# STM32H7S register map
File version: 1.0
CPU: CM7 r0p1, little endian, MPU, FPU, 4 interrupt priority bits
Registers are 32-bit, read-write, reset 0x0 unless marked. A register's access mark holds for its fields unless they carry their own. Offsets are from the block's base; [hi:lo] are bit positions; <NAME> marks a mode.

## TIM13 — General-purpose timers
Base 0x40001C00
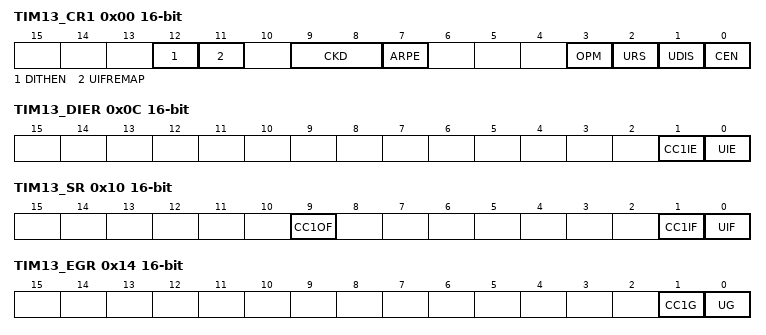
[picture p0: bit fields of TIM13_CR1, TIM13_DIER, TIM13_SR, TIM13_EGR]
0x00 TIM13_CR1 16-bit — TIM13 control register 1
  [12] DITHEN — Dithering enable Note: The DITHEN bit can only be modified when CEN bit is reset.
    0=Dithering disabled; 1=Dithering enabled
  [11] UIFREMAP — UIF status bit remapping
    0=No remapping. UIF status bit is not copied to TIMx_CNT register bit 31.; 1=Remapping enabled. UIF status bit is copied to TIMx_CNT register bit 31.
  [9:8] CKD — Clock division This bit-field indicates the division ratio between the timer clock (tim_ker_ck) frequency and sampling clock used by the digital filters (tim_tix),
    0=t<sub>DTS</sub> = t<sub>tim_ker_ck</sub>; 1=t<sub>DTS</sub> = 2 t<sub>tim_ker_ck</sub>; 2=t<sub>DTS</sub> = 4 t<sub>tim_ker_ck</sub>; 3=FIELD Reserved
  [7] ARPE — Auto-reload preload enable
    0=TIMx_ARR register is not buffered; 1=TIMx_ARR register is buffered
  [3] OPM — One-pulse mode
    0=Counter is not stopped on the update event; 1=Counter stops counting on the next update event (clearing the CEN bit)
  [2] URS — Update request source This bit is set and cleared by software to select the update interrupt (UEV) sources. Counter overflow Setting the UG bit
    0=Any of the following events generate an UEV if enabled:; 1=Only counter overflow generates an UEV if enabled
  [1] UDIS — Update disable This bit is set and cleared by software to enable/disable update interrupt (UEV) event generation. Counter overflow Setting the UG bit. Buffered registers are then loaded with their preload values.
    0=UEV enabled. An UEV is generated by one of the following events:; 1=UEV disabled. No UEV is generated, shadow registers keep their value (ARR, PSC, CCRx). The counter and the prescaler are reinitialized if the UG bit is set.
  [0] CEN — Counter enable Note: External clock and gated mode can work only if the CEN bit has been previously set by software. However trigger mode can set the CEN bit automatically by hardware.
    0=Counter disabled; 1=Counter enabled
0x0C TIM13_DIER 16-bit — TIM13 Interrupt enable register
  [1] CC1IE — Capture/Compare 1 interrupt enable
    0=CC1 interrupt disabled; 1=CC1 interrupt enabled
  [0] UIE — Update interrupt enable
    0=Update interrupt disabled; 1=Update interrupt enabled
0x10 TIM13_SR 16-bit — TIM13 status register
  [9] CC1OF — Capture/Compare 1 overcapture flag This flag is set by hardware only when the corresponding channel is configured in input capture mode. It is cleared by software by writing it to 0.
    0=No overcapture has been detected; 1=The counter value has been captured in TIMx_CCR1 register while CC1IF flag was already set
  [1] CC1IF — Capture/compare 1 interrupt flag This flag is set by hardware. It is cleared by software (input capture or output compare mode) or by reading the TIMx_CCR1 register (input capture mode only). If channel CC1 is configured as output: this flag is set when he content of the counter TIMx_CNT matches the content of the TIMx_CCR1 register. When the content of TIMx_CCR1 is greater than the content of TIMx_ARR, the CC1IF bit goes high on the counter overflow (in up-counting and up/down-counting modes) or underflow (in down-counting mode). There are 3 possible options for flag setting in center-aligned mode, refer to the CMS bits in the TIMx_CR1 register for the full description. If channel CC1 is configured as input: this bit is set when counter value has been captured in TIMx_CCR1 register (an edge has been detected on tim_ic1, as per the edge sensitivity defined with the CC1P and CC1NP bits setting, in TIMx_CCER).
    0=No compare match / No input capture occurred; 1=A compare match or an input capture occurred
  [0] UIF — Update interrupt flag This bit is set by hardware on an update event. It is cleared by software. At overflow and if UDIS=0 in the TIMx_CR1 register. When CNT is reinitialized by software using the UG bit in TIMx_EGR register, if URS=0 and UDIS=0 in the TIMx_CR1 register.
    0=No update occurred; 1=Update interrupt pending. This bit is set by hardware when the registers are updated:
0x14 TIM13_EGR 16-bit wo — TIM13 event generation register
  [1] CC1G — Capture/compare 1 generation This bit is set by software in order to generate an event, it is automatically cleared by hardware. If channel CC1 is configured as output: CC1IF flag is set, Corresponding interrupt or is sent if enabled. If channel CC1 is configured as input: The current value of the counter is captured in TIMx_CCR1 register. The CC1IF flag is set, the corresponding interrupt is sent if enabled. The CC1OF flag is set if the CC1IF flag was already high.
    0=No action; 1=A capture/compare event is generated on channel 1:
  [0] UG — Update generation This bit can be set by software, it is automatically cleared by hardware.
    0=No action; 1=Re-initialize the counter and generates an update of the registers. Note that the prescaler counter is cleared too (anyway the prescaler ratio is not affected). The counter is cleared.
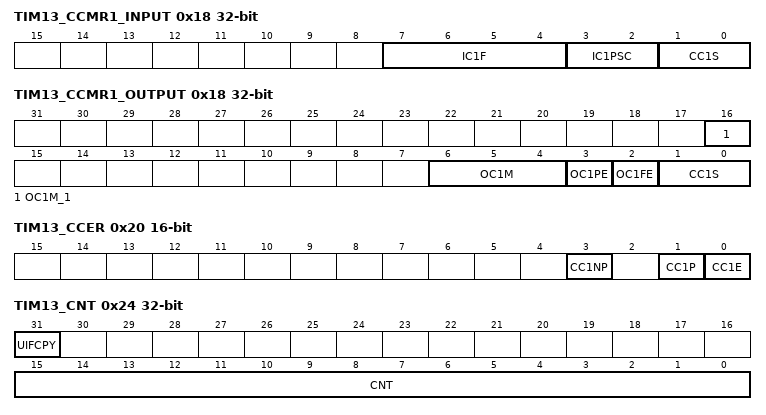
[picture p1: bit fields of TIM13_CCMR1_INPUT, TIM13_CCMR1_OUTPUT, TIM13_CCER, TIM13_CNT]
0x18 TIM13_CCMR1_INPUT — TIM13 capture/compare mode register 1
  [7:4] IC1F — Input capture 1 filter This bit-field defines the frequency used to sample tim_ti1 input and the length of the digital filter applied to tim_ti1. The digital filter is made of an event counter in which N consecutive events are needed to validate a transition on the output:
    0=No filter, sampling is done at f<sub>DTS</sub>; 1=f<sub>SAMPLING</sub>=f<sub>tim_ker_ck</sub>, N=2; 2=f<sub>SAMPLING</sub>=f<sub>tim_ker_ck</sub>, N=4; 3=f<sub>SAMPLING</sub>=f<sub>tim_ker_ck</sub>, N=8; 4=f<sub>SAMPLING</sub>=f<sub>DTS</sub>/2, N=6; 5=f<sub>SAMPLING</sub>=f<sub>DTS</sub>/2, N=8; 6=f<sub>SAMPLING</sub>=f<sub>DTS</sub>/4, N=6; 7=f<sub>SAMPLING</sub>=f<sub>DTS</sub>/4, N=8; 8=f<sub>SAMPLING</sub>=f<sub>DTS</sub>/8, N=6; 9=f<sub>SAMPLING</sub>=f<sub>DTS</sub>/8, N=8; 10=f<sub>SAMPLING</sub>=f<sub>DTS</sub>/16, N=5; 11=f<sub>SAMPLING</sub>=f<sub>DTS</sub>/16, N=6; 12=f<sub>SAMPLING</sub>=f<sub>DTS</sub>/16, N=8; 13=f<sub>SAMPLING</sub>=f<sub>DTS</sub>/32, N=5; 14=f<sub>SAMPLING</sub>=f<sub>DTS</sub>/32, N=6; 15=f<sub>SAMPLING</sub>=f<sub>DTS</sub>/32, N=8
  [3:2] IC1PSC — Input capture 1 prescaler This bit-field defines the ratio of the prescaler acting on CC1 input (tim_ic1). The prescaler is reset as soon as CC1E=0 (TIMx_CCER register).
    0=no prescaler, capture is done each time an edge is detected on the capture input; 1=capture is done once every 2 events; 2=capture is done once every 4 events; 3=capture is done once every 8 events
  [1:0] CC1S — Capture/Compare 1 selection This bit-field defines the direction of the channel (input/output) as well as the used input. Note: CC1S bits are writable only when the channel is OFF (CC1E = 0 in TIMx_CCER).
    0=CC1 channel is configured as output; 1=CC1 channel is configured as input, tim_ic1 is mapped on tim_ti1; 2=FIELD Reserved; 3=FIELD Reserved
0x18 TIM13_CCMR1_OUTPUT (alternate view of TIM13_CCMR1_INPUT) — TIM13 capture/compare mode register 1
  [16] OC1M_1 — OC1M[3]
  [6:4] OC1M — OC1M[2:0]: Output compare 1 mode (refer to bit 16 for OC1M[3]) These bits define the behavior of the output reference signal tim_oc1ref from which tim_oc1 is derived. tim_oc1ref is active high whereas tim_oc1 active level depends on CC1P bit. Others: Reserved Note: In PWM mode 1 or 2, the OCREF level changes when the result of the comparison changes or when the output compare mode switches from frozen to PWM mode.
    0=Frozen. The comparison between the output compare register TIMx_CCR1 and the counter TIMx_CNT has no effect on the outputs.; 1=Set channel 1 to active level on match. tim_oc1ref signal is forced high when the counter TIMx_CNT matches the capture/compare register 1 (TIMx_CCR1).; 2=Set channel 1 to inactive level on match. tim_oc1ref signal is forced low when the counter TIMx_CNT matches the capture/compare register 1 (TIMx_CCR1).; 3=Toggle - tim_oc1ref toggles when TIMx_CNT = TIMx_CCR1; 4=Force inactive level - tim_oc1ref is forced low; 5=Force active level - tim_oc1ref is forced high; 6=PWM mode 1 - Channel 1 is active as long as TIMx_CNT < TIMx_CCR1 else inactive; 7=PWM mode 2 - Channel 1 is inactive as long as TIMx_CNT < TIMx_CCR1 else active
  [3] OC1PE — Output compare 1 preload enable
    0=Preload register on TIMx_CCR1 disabled. TIMx_CCR1 can be written at anytime, the new value is taken in account immediately.; 1=Preload register on TIMx_CCR1 enabled. Read/Write operations access the preload register. TIMx_CCR1 preload value is loaded in the active register at each update event.
  [2] OC1FE — Output compare 1 fast enable This bit decreases the latency between a trigger event and a transition on the timer output. It must be used in one-pulse mode (OPM bit set in TIMx_CR1 register), to have the output pulse starting as soon as possible after the starting trigger.
    0=CC1 behaves normally depending on counter and CCR1 values even when the trigger is ON. The minimum delay to activate CC1 output when an edge occurs on the trigger input is 5 clock cycles.; 1=An active edge on the trigger input acts like a compare match on CC1 output. OC is then set to the compare level independently of the result of the comparison. Delay to sample the trigger input and to activate CC1 output is reduced to 3 clock cycles. OC1FE acts only if the channel is configured in PWM1 or PWM2 mode.
  [1:0] CC1S — Capture/Compare 1 selection This bit-field defines the direction of the channel (input/output) as well as the used input. Note: CC1S bits are writable only when the channel is OFF (CC1E = 0 in TIMx_CCER).
    0=CC1 channel is configured as output; 1=CC1 channel is configured as input, tim_ic1 is mapped on tim_ti1
0x20 TIM13_CCER 16-bit — TIM13 capture/compare enable register
  [3] CC1NP — Capture/Compare 1 complementary output Polarity. CC1 channel configured as output: CC1NP must be kept cleared. CC1 channel configured as input: CC1NP bit is used in conjunction with CC1P to define tim_ti1fp1 polarity (refer to CC1P description).
  [1] CC1P — Capture/Compare 1 output Polarity. When CC1 channel is configured as input, both CC1NP/CC1P bits select the active polarity of tim_ti1fp1 for capture operations. CC1NP=0, CC1P=0: non-inverted/rising edge. The circuit is sensitive to tim_ti1fp1 rising edge (capture or trigger operations in reset, external clock or trigger mode), TIxFP1 is not inverted (trigger operation in gated mode or encoder mode). CC1NP=0, CC1P=1: inverted/falling edge. The circuit is sensitive to tim_ti1fp1 falling edge (capture or trigger operations in reset, external clock or trigger mode), tim_ti1fp1 is inverted (trigger operation in gated mode or encoder mode). CC1NP=1, CC1P=1: non-inverted/both edges/ The circuit is sensitive to both tim_ti1fp1 rising and falling edges (capture or trigger operations in reset, external clock or trigger mode), tim_ti1fp1 not inverted (trigger operation in gated mode). This configuration must not be used in encoder mode. CC1NP=1, CC1P=0: This configuration is reserved, it must not be used.
    0=tim_oc1 active high (output mode) / Edge sensitivity selection (input mode, see below); 1=tim_oc1 active low (output mode) / Edge sensitivity selection (input mode, see below)
  [0] CC1E — Capture/Compare 1 output enable.
    0=Capture mode disabled / tim_oc1 is not active; 1=Capture mode enabled / tim_oc1 signal is output on the corresponding output pin
0x24 TIM13_CNT — TIM13 counter
  [31] UIFCPY — UIF Copy This bit is a read-only copy of the UIF bit in the TIMx_ISR register.
  [15:0] CNT — Counter value Non-dithering mode (DITHEN = 0) The register holds the counter value. Dithering mode (DITHEN = 1) The register only holds the non-dithered part in CNT[15:0]. The fractional part is not available.
0x28 TIM13_PSC 16-bit — TIM13 prescaler
  [15:0] PSC — Prescaler value The counter clock frequency tim_cnt_ck is equal to f<sub>tim_psc_ck</sub> / (PSC[15:0] + 1). PSC contains the value to be loaded in the active prescaler register at each update event. (including when the counter is cleared through UG bit of TIMx_EGR register or through trigger controller when configured in reset mode).
0x2C TIM13_ARR reset 0xFFFF — TIM13 auto-reload register
  [19:0] ARR — Auto-reload value ARR is the value to be loaded in the actual auto-reload register. Refer to the Section 67.4.3: Time-base unit on page 3951 for more details about ARR update and behavior. The counter is blocked while the auto-reload value is null. Non-dithering mode (DITHEN = 0) The register holds the auto-reload value in ARR[15:0]. The ARR[19:16] bits are reset. Dithering mode (DITHEN = 1) The register holds the integer part in ARR[19:4]. The ARR[3:0] bitfield contains the dithered part.
0x34 TIM13_CCR1 — TIM13 capture/compare register 1
  [19:0] CCR1 — Capture/compare 1 value If channel CC1 is configured as output: CCR1 is the value to be loaded in the actual capture/compare 1 register (preload value). It is loaded permanently if the preload feature is not selected in the TIMx_CCMR1 register (bit OC1PE). Else the preload value is copied in the active capture/compare 1 register when an update event occurs. The active capture/compare register contains the value to be compared to the counter TIMx_CNT and signaled on tim_oc1 output. Non-dithering mode (DITHEN = 0) The register holds the compare value in CCR1[15:0]. The CCR1[19:16] bits are reset. Dithering mode (DITHEN = 1) The register holds the integer part in CCR1[19:4]. The CCR1[3:0] bitfield contains the dithered part. If channel CC1 is configured as input: CR1 is the counter value transferred by the last input capture 1 event (tim_ic1). The TIMx_CCR1 register is read-only and cannot be programmed. Non-dithering mode (DITHEN = 0) The register holds the capture value in CCR1[15:0]. The CCR1[19:16] bits are reset. Dithering mode (DITHEN = 1) The register holds the capture in CCR1[19:4]. The CCR1[3:0] bits are reset.
0x5C TIM13_TISEL 16-bit — TIM13 timer input selection register
  [3:0] TI1SEL — selects tim_ti1_in[15:0] input ... Refer to Table 656: Interconnect to the tim_ti1 input multiplexer for interconnects list.
    0=TIMx_CH1 input (tim_ti1_in0); 1=tim_ti1_in1; 15=tim_ti1_in15

## TIM14 — General-purpose timers
Base 0x40002000
Registers as TIM13 (with TIM13 read as TIM14).
